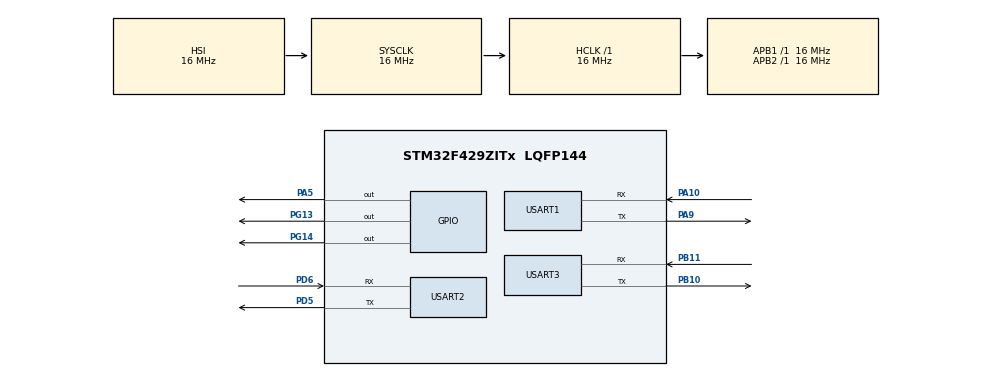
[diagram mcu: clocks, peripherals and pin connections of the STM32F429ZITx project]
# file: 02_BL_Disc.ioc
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Mcu.Family=STM32F4
Mcu.Name=STM32F429ZITx
Mcu.Package=LQFP144
NVIC.FLASH_IRQn=true\:0\:0\:false\:false\:true\:true\:true\:true
NVIC.FPU_IRQn=true\:0\:0\:false\:false\:true\:true\:false\:true
NVIC.PVD_IRQn=true\:0\:0\:false\:false\:true\:true\:true\:true
NVIC.PriorityGroup=NVIC_PRIORITYGROUP_4
NVIC.RCC_IRQn=true\:0\:0\:false\:false\:true\:true\:false\:true
NVIC.USART1_IRQn=true\:0\:0\:false\:false\:true\:true\:true\:true
NVIC.USART2_IRQn=true\:0\:0\:false\:false\:true\:true\:true\:true
NVIC.USART3_IRQn=true\:0\:0\:false\:false\:true\:true\:true\:true
PA10.Mode=Asynchronous
PA10.Signal=USART1_RX
PA5.Signal=GPIO_Output
PA9.Mode=Asynchronous
PA9.Signal=USART1_TX
PB10.Mode=Asynchronous
PB10.Signal=USART3_TX
PB11.Mode=Asynchronous
PB11.Signal=USART3_RX
PC14/OSC32_IN.Mode=LSE-External-Oscillator
PC14/OSC32_IN.Signal=RCC_OSC32_IN
PC15/OSC32_OUT.Mode=LSE-External-Oscillator
PC15/OSC32_OUT.Signal=RCC_OSC32_OUT
PD5.Mode=Asynchronous
PD5.Signal=USART2_TX
PD6.Mode=Asynchronous
PD6.Signal=USART2_RX
PG13.Signal=GPIO_Output
PG14.Signal=GPIO_Output
PH0/OSC_IN.Mode=HSE-External-Oscillator
PH0/OSC_IN.Signal=RCC_OSC_IN
PH1/OSC_OUT.Mode=HSE-External-Oscillator
PH1/OSC_OUT.Signal=RCC_OSC_OUT
ProjectManager.HeapSize=0x200
ProjectManager.StackSize=0x400
ProjectManager.TargetToolchain=STM32CubeIDE
RCC.AHBFreq_Value=16000000
RCC.APB1Freq_Value=16000000
RCC.APB2Freq_Value=16000000
RCC.CortexFreq_Value=16000000
RCC.HSE_VALUE=25000000
RCC.HSI_VALUE=16000000
RCC.SYSCLKFreq_VALUE=16000000
RCC.VCOOutputFreq_Value=192000000
USART1.VirtualMode=VM_ASYNC
USART2.VirtualMode=VM_ASYNC
USART3.VirtualMode=VM_ASYNC
VP_CRC_VS_CRC.Mode=CRC_Activate
board=custom

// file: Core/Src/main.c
/* USER CODE BEGIN Header */
/**
  ******************************************************************************
  * @file           : main.c
  * @brief          : Main program body
  ******************************************************************************
  * @attention
  *
  * Copyright (c) 2024 STMicroelectronics.
  * All rights reserved.
  *
  * This software is licensed under terms that can be found in the LICENSE file
  * in the root directory of this software component.
  * If no LICENSE file comes with this software, it is provided AS-IS.
  *
  ******************************************************************************
  */
/* USER CODE END Header */
#include "main.h"
#include "crc.h"
#include "usart.h"
#include "gpio.h"

void SystemClock_Config(void);

volatile uint8_t indecator_Var, dummy;

void toggleBankAndReset() {
	FLASH_AdvOBProgramInitTypeDef OBInit;
	HAL_FLASH_Unlock();
	//__HAL_FLASH_CLEAR_FLAG(FLASH_FLAG_OPTVERR);
	HAL_FLASH_OB_Unlock();
	HAL_FLASHEx_AdvOBGetConfig(&OBInit);
	OBInit.OptionType = OPTIONBYTE_BOOTCONFIG;

	if (((OBInit.BootConfig) & (OB_DUAL_BOOT_ENABLE)) == OB_DUAL_BOOT_ENABLE) {
		OBInit.BootConfig = OB_DUAL_BOOT_DISABLE;
	} else {
		OBInit.BootConfig = OB_DUAL_BOOT_ENABLE;
	}
	if (HAL_FLASHEx_AdvOBProgram(&OBInit) != HAL_OK) {

		while (1) {
			HAL_Delay(1000);
			HAL_GPIO_TogglePin(GPIOG, GPIO_PIN_14);
		}
	}
	if (HAL_FLASH_OB_Launch() != HAL_OK) {

		while (1) {
			HAL_Delay(100);
			HAL_GPIO_TogglePin(GPIOG, GPIO_PIN_14);
		}
	}
	HAL_FLASH_OB_Lock();
	HAL_FLASH_Lock();
	HAL_NVIC_SystemReset();

}

int _write(int file, char *ptr, int len)
{
  /* Implement your write code here, this is used by puts and printf for example */
  int i=0;
  for(i=0 ; i<len ; i++)
    ITM_SendChar((*ptr++));
  return len;
}

uint32_t get_Active_Bank_no(void) {
	uint32_t checkBank = READ_BIT(SYSCFG->MEMRMP, SYSCFG_MEMRMP_UFB_MODE);
	if (checkBank == 0) {
		 HAL_GPIO_WritePin(GPIOG, GPIO_PIN_14, 1);
	} else {
		 HAL_GPIO_WritePin(GPIOG, GPIO_PIN_13, 1);
	}
	return checkBank;
}

int main(void)
{

  /* MCU Configuration--------------------------------------------------------*/
printf("starting\n\r");
  /* Reset of all peripherals, Initializes the Flash interface and the Systick. */
  HAL_Init();

  /* Configure the system clock */
  SystemClock_Config();

  /* Initialize all configured peripherals */
  MX_GPIO_Init();
  MX_USART2_UART_Init();
  MX_USART1_UART_Init();
  MX_CRC_Init();
  MX_USART3_UART_Init();
  /* USER CODE BEGIN 2 */
 // Check_ProgrammingFlag();
  /* USER CODE END 2 */

  /* Infinite loop */
  /* USER CODE BEGIN WHILE */

HAL_GPIO_WritePin(GPIOG, GPIO_PIN_14,1);
//Perform_Flash_Erase(0,3);
//HAL_GPIO_WritePin(GPIOG, GPIO_PIN_13,1);

  while (1)
  {
    /* USER CODE END WHILE */

    /* USER CODE BEGIN 3 */

	  HAL_UART_Receive(&huart3, &indecator_Var, 1, HAL_MAX_DELAY);
	    				if (0x7F == indecator_Var)
	    				    BL_UART_Fetch_Host_Command();

  }
  /* USER CODE END 3 */
}

void SystemClock_Config(void)
{
  RCC_OscInitTypeDef RCC_OscInitStruct = {0};
  RCC_ClkInitTypeDef RCC_ClkInitStruct = {0};

  /** Configure the main internal regulator output voltage
  */
  __HAL_RCC_PWR_CLK_ENABLE();
  __HAL_PWR_VOLTAGESCALING_CONFIG(PWR_REGULATOR_VOLTAGE_SCALE3);

  /** Initializes the RCC Oscillators according to the specified parameters
  * in the RCC_OscInitTypeDef structure.
  */
  RCC_OscInitStruct.OscillatorType = RCC_OSCILLATORTYPE_HSI;
  RCC_OscInitStruct.HSIState = RCC_HSI_ON;
  RCC_OscInitStruct.HSICalibrationValue = RCC_HSICALIBRATION_DEFAULT;
  RCC_OscInitStruct.PLL.PLLState = RCC_PLL_NONE;
  if (HAL_RCC_OscConfig(&RCC_OscInitStruct) != HAL_OK)
  {
    Error_Handler();
  }

  /** Initializes the CPU, AHB and APB buses clocks
  */
  RCC_ClkInitStruct.ClockType = RCC_CLOCKTYPE_HCLK|RCC_CLOCKTYPE_SYSCLK
                              |RCC_CLOCKTYPE_PCLK1|RCC_CLOCKTYPE_PCLK2;
  RCC_ClkInitStruct.SYSCLKSource = RCC_SYSCLKSOURCE_HSI;
  RCC_ClkInitStruct.AHBCLKDivider = RCC_SYSCLK_DIV1;
  RCC_ClkInitStruct.APB1CLKDivider = RCC_HCLK_DIV1;
  RCC_ClkInitStruct.APB2CLKDivider = RCC_HCLK_DIV1;

  if (HAL_RCC_ClockConfig(&RCC_ClkInitStruct, FLASH_LATENCY_0) != HAL_OK)
  {
    Error_Handler();
  }
}

void Error_Handler(void)
{
  __disable_irq();
  while (1)
  {
  }
}
